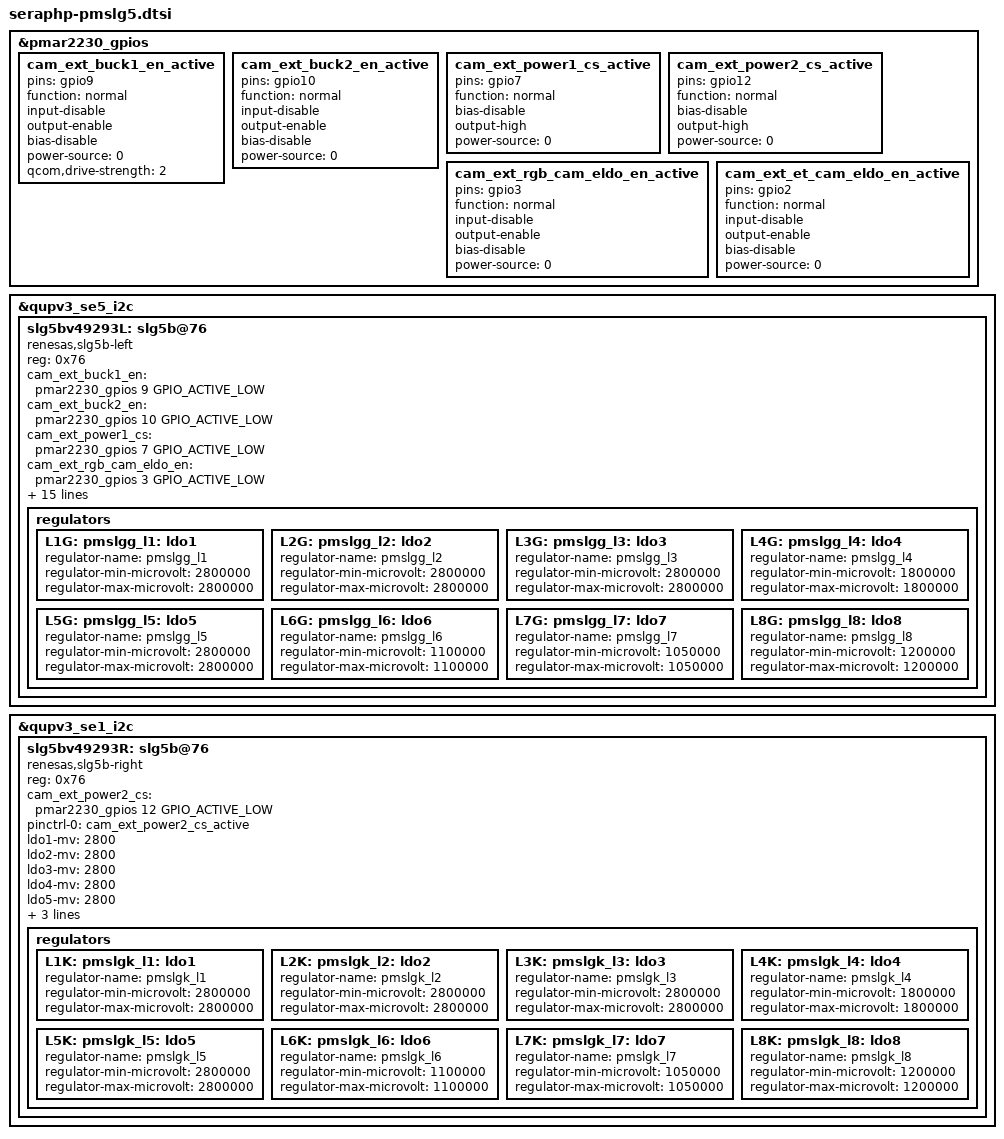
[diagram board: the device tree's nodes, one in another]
// SPDX-License-Identifier: BSD-3-Clause
/*
 * Copyright (c) Qualcomm Technologies, Inc. and/or its subsidiaries.
 */

#include <dt-bindings/gpio/gpio.h>
#include <dt-bindings/interrupt-controller/irq.h>

&pmar2230_gpios {
	cam_ext_buck1_en_active: cam_ext_buck1_en_active {
		pins = "gpio9";
		function = "normal";
		input-disable;
		output-enable;
		bias-disable;
		power-source = <0>;
		qcom,drive-strength = <2>;
	};

	cam_ext_buck2_en_active: cam_ext_buck2_en_active {
		pins = "gpio10";
		function = "normal";
		input-disable;
		output-enable;
		bias-disable;
		power-source = <0>;
	};

	cam_ext_power1_cs_active: cam_ext_power1_cs_active {
		pins = "gpio7";
		function = "normal";
		bias-disable;
		output-high;
		power-source = <0>;
	};

	cam_ext_power2_cs_active: cam_ext_power2_cs_active {
		pins = "gpio12";
		function = "normal";
		bias-disable;
		output-high;
		power-source = <0>;
	};

	cam_ext_rgb_cam_eldo_en_active: cam_ext_rgb_cam_eldo_en_active {
		pins = "gpio3";
		function = "normal";
		input-disable;
		output-enable;
		bias-disable;
		power-source = <0>;
	};

	cam_ext_et_cam_eldo_en_active: cam_ext_et_cam_eldo_en_active {
		pins = "gpio2";
		function = "normal";
		input-disable;
		output-enable;
		bias-disable;
		power-source = <0>;
	};
};

&qupv3_se5_i2c {
	status = "ok";
	#address-cells = <1>;
	#size-cells = <0>;

	slg5bv49293L: slg5b@76 {
		compatible = "renesas,slg5b-left";
		reg = <0x76>;
		cam_ext_buck1_en = <&pmar2230_gpios 9 GPIO_ACTIVE_LOW>;
		cam_ext_buck2_en = <&pmar2230_gpios 10 GPIO_ACTIVE_LOW>;
		cam_ext_power1_cs = <&pmar2230_gpios 7 GPIO_ACTIVE_LOW>;
		cam_ext_rgb_cam_eldo_en = <&pmar2230_gpios 3 GPIO_ACTIVE_LOW>;
		cam_ext_et_cam_eldo_en = <&pmar2230_gpios 2 GPIO_ACTIVE_LOW>;
		pinctrl-names = "default";
		pinctrl-0 = <&cam_ext_buck1_en_active
			&cam_ext_buck2_en_active
			&cam_ext_power1_cs_active
			&cam_ext_rgb_cam_eldo_en_active
			&cam_ext_et_cam_eldo_en_active>;
		ldo1-mv = <2800>;/* 2.8V */
		ldo2-mv = <2800>;/* 2.8V */
		ldo3-mv = <2800>;/* 2.8V */
		ldo4-mv = <2800>;/* 2.8V */
		ldo5-mv = <2800>;/* 2.8V */
		ldo6-mv = <1200>;/* 1.2V */
		ldo7-mv = <1200>;/* 1.2V */
		ldo8-mv = <1200>;/* 1.2V */

		regulators {
			L1G: pmslgg_l1: ldo1 {
				regulator-name = "pmslgg_l1";
				regulator-min-microvolt = <2800000>;
				regulator-max-microvolt = <2800000>;
			};

			L2G: pmslgg_l2: ldo2 {
				regulator-name = "pmslgg_l2";
				regulator-min-microvolt = <2800000>;
				regulator-max-microvolt = <2800000>;
			};

			L3G: pmslgg_l3: ldo3 {
				regulator-name = "pmslgg_l3";
				regulator-min-microvolt = <2800000>;
				regulator-max-microvolt = <2800000>;
			};

			L4G: pmslgg_l4: ldo4 {
				regulator-name = "pmslgg_l4";
				regulator-min-microvolt = <1800000>;
				regulator-max-microvolt = <1800000>;
			};

			L5G: pmslgg_l5: ldo5 {
				regulator-name = "pmslgg_l5";
				regulator-min-microvolt = <2800000>;
				regulator-max-microvolt = <2800000>;
			};

			L6G: pmslgg_l6: ldo6 {
				regulator-name = "pmslgg_l6";
				regulator-min-microvolt = <1100000>;
				regulator-max-microvolt = <1100000>;
			};

			L7G: pmslgg_l7: ldo7 {
				regulator-name = "pmslgg_l7";
				regulator-min-microvolt = <1050000>;
				regulator-max-microvolt = <1050000>;
			};

			L8G: pmslgg_l8: ldo8 {
				regulator-name = "pmslgg_l8";
				regulator-min-microvolt = <1200000>;
				regulator-max-microvolt = <1200000>;
			};
		};
	};
};

&qupv3_se1_i2c {
	status = "ok";
	#address-cells = <1>;
	#size-cells = <0>;

	slg5bv49293R: slg5b@76 {
		compatible = "renesas,slg5b-right";
		reg = <0x76>;
		cam_ext_power2_cs = <&pmar2230_gpios 12 GPIO_ACTIVE_LOW>;
		pinctrl-names = "default";
		pinctrl-0 = <&cam_ext_power2_cs_active>;
		ldo1-mv = <2800>;/* 2.8V */
		ldo2-mv = <2800>;/* 2.8V */
		ldo3-mv = <2800>;/* 2.8V */
		ldo4-mv = <2800>;/* 2.8V */
		ldo5-mv = <2800>;/* 2.8V */
		ldo6-mv = <1200>;/* 1.2V */
		ldo7-mv = <1200>;/* 1.2V */
		ldo8-mv = <1200>;/* 1.2V */

		regulators {
			L1K: pmslgk_l1: ldo1 {
				regulator-name = "pmslgk_l1";
				regulator-min-microvolt = <2800000>;
				regulator-max-microvolt = <2800000>;
			};

			L2K: pmslgk_l2: ldo2 {

				regulator-name = "pmslgk_l2";
				regulator-min-microvolt = <2800000>;
				regulator-max-microvolt = <2800000>;
			};

			L3K: pmslgk_l3: ldo3 {
				regulator-name = "pmslgk_l3";
				regulator-min-microvolt = <2800000>;
				regulator-max-microvolt = <2800000>;
			};

			L4K: pmslgk_l4: ldo4 {
				regulator-name = "pmslgk_l4";
				regulator-min-microvolt = <1800000>;
				regulator-max-microvolt = <1800000>;
			};

			L5K: pmslgk_l5: ldo5 {
				regulator-name = "pmslgk_l5";
				regulator-min-microvolt = <2800000>;
				regulator-max-microvolt = <2800000>;
			};

			L6K: pmslgk_l6: ldo6 {
				regulator-name = "pmslgk_l6";
				regulator-min-microvolt = <1100000>;
				regulator-max-microvolt = <1100000>;
			};

			L7K: pmslgk_l7: ldo7 {
				regulator-name = "pmslgk_l7";
				regulator-min-microvolt = <1050000>;
				regulator-max-microvolt = <1050000>;
			};

			L8K: pmslgk_l8: ldo8 {
				regulator-name = "pmslgk_l8";
				regulator-min-microvolt = <1200000>;
				regulator-max-microvolt = <1200000>;
			};
		};
	};
};
